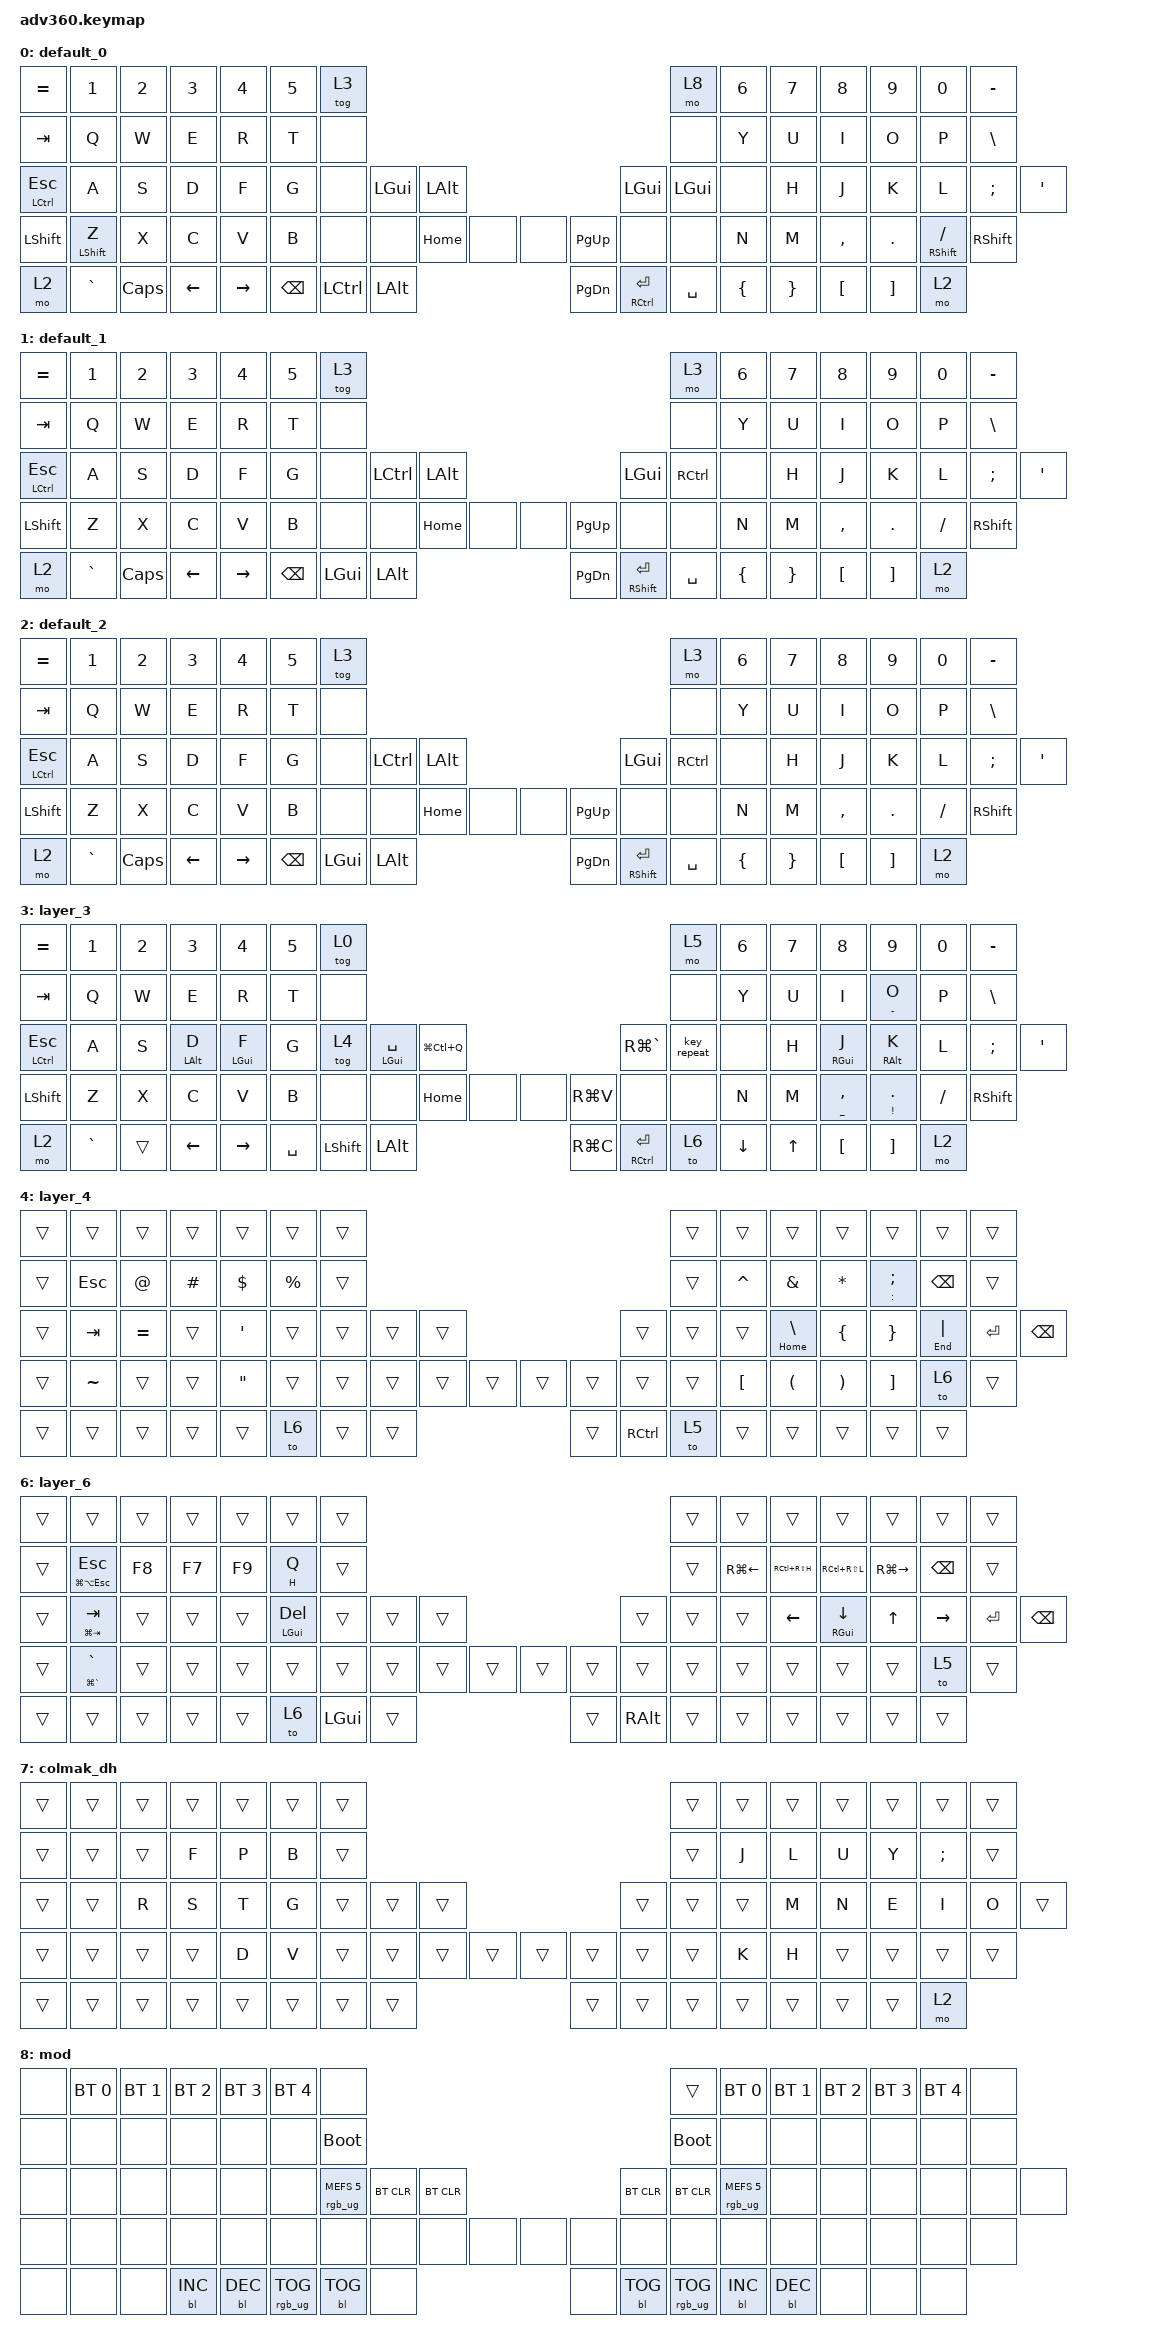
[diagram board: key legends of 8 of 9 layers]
#include <behaviors.dtsi>
#include <dt-bindings/zmk/keys.h>
#include <dt-bindings/zmk/bt.h>
#include <dt-bindings/zmk/rgb.h>
#include <dt-bindings/zmk/backlight.h>

/ {
    behaviors {
        #include "macros.dtsi"

        hm: homerow_mods {
            compatible = "zmk,behavior-hold-tap";
            label = "HOMEROW_MODS";
            #binding-cells = <2>;
            tapping-term-ms = <250>;
            quick_tap_ms = <0>;
            flavor = "tap-preferred";
            bindings =
                <&kp>,
                <&kp>;
        };
        td: tapdance {
            compatible = "zmk,behavior-hold-tap";
            label = "TAPDANCE";
            #binding-cells = <2>;
            tapping-term-ms = <175>;
            quick_tap_ms = <0>;
            flavor = "tap-preferred";
            bindings = <&kp>, <&kp>;
        };
    };

    keymap {
        compatible = "zmk,keymap";

        default_0 {
            bindings = <
            &kp EQUAL     &kp N1    &kp N2    &kp N3     &kp N4  &kp N5    &tog 3                                                                             &mo 8  &kp N6          &kp N7           &kp N8    &kp N9    &kp N0  &kp MINUS
              &kp TAB      &kp Q     &kp W     &kp E      &kp R   &kp T     &none                                                                             &none   &kp Y           &kp U            &kp I     &kp O     &kp P   &kp BSLH
 &hm LEFT_CONTROL ESC      &kp A     &kp S     &kp D      &kp F   &kp G     &none  &kp LGUI  &kp LALT                   &kp LGUI              &kp LGUI      &none   &kp H           &kp J            &kp K     &kp L  &kp SEMI    &kp SQT
            &kp LSHFT      &hm LSHFT Z     &kp X     &kp C      &kp V   &kp B     &none      &none  &kp HOME   &none   &none  &kp PG_UP                  &none      &none   &kp N           &kp M        &kp COMMA   &kp DOT  &hm RSHFT FSLH  &kp RSHFT
                &mo 2  &kp GRAVE  &kp CAPS  &kp LEFT  &kp RIGHT          &kp BSPC   &kp LCTRL  &kp LALT                  &kp PG_DN  &hm RCTRL ENTER  &kp SPACE          &kp LEFT_BRACE  &kp RIGHT_BRACE  &kp LBKT  &kp RBKT      &mo 2
            >;
        };

        default_1 {
            bindings = <
            &kp EQUAL     &kp N1    &kp N2    &kp N3     &kp N4  &kp N5    &tog 3                                                                             &mo 3  &kp N6          &kp N7           &kp N8    &kp N9    &kp N0  &kp MINUS
              &kp TAB      &kp Q     &kp W     &kp E      &kp R   &kp T     &none                                                                             &none   &kp Y           &kp U            &kp I     &kp O     &kp P   &kp BSLH
 &hm LEFT_CONTROL ESC      &kp A     &kp S     &kp D      &kp F   &kp G     &none  &kp LCTRL  &kp LALT                   &kp LGUI              &kp RCTRL      &none   &kp H           &kp J            &kp K     &kp L  &kp SEMI    &kp SQT
            &kp LSHFT      &kp Z     &kp X     &kp C      &kp V   &kp B     &none      &none  &kp HOME   &none   &none  &kp PG_UP                  &none      &none   &kp N           &kp M        &kp COMMA   &kp DOT  &kp FSLH  &kp RSHFT
                &mo 2  &kp GRAVE  &kp CAPS  &kp LEFT  &kp RIGHT          &kp BSPC   &kp LGUI  &kp LALT                  &kp PG_DN  &mt RIGHT_SHIFT ENTER  &kp SPACE          &kp LEFT_BRACE  &kp RIGHT_BRACE  &kp LBKT  &kp RBKT      &mo 2
            >;
        };

        default_2 {
            bindings = <
            &kp EQUAL     &kp N1    &kp N2    &kp N3     &kp N4  &kp N5    &tog 3                                                                             &mo 3  &kp N6          &kp N7           &kp N8    &kp N9    &kp N0  &kp MINUS
              &kp TAB      &kp Q     &kp W     &kp E      &kp R   &kp T     &none                                                                             &none   &kp Y           &kp U            &kp I     &kp O     &kp P   &kp BSLH
 &hm LEFT_CONTROL ESC      &kp A     &kp S     &kp D      &kp F   &kp G     &none  &kp LCTRL  &kp LALT                   &kp LGUI              &kp RCTRL      &none   &kp H           &kp J            &kp K     &kp L  &kp SEMI    &kp SQT
            &kp LSHFT      &kp Z     &kp X     &kp C      &kp V   &kp B     &none      &none  &kp HOME   &none   &none  &kp PG_UP                  &none      &none   &kp N           &kp M        &kp COMMA   &kp DOT  &kp FSLH  &kp RSHFT
                &mo 2  &kp GRAVE  &kp CAPS  &kp LEFT  &kp RIGHT          &kp BSPC   &kp LGUI  &kp LALT                  &kp PG_DN  &mt RIGHT_SHIFT ENTER  &kp SPACE          &kp LEFT_BRACE  &kp RIGHT_BRACE  &kp LBKT  &kp RBKT      &mo 2
            >;
        };

        layer_3 {
            bindings = <
            &kp EQUAL     &kp N1  &kp N2    &kp N3     &kp N4  &kp N5  &tog 0                                                                                        &mo 5  &kp N6    &kp N7     &kp N8    &kp N9    &kp N0  &kp MINUS
              &kp TAB      &kp Q   &kp W     &kp E      &kp R   &kp T   &none                                                                                        &none   &kp Y     &kp U      &kp I     &td MINUS O     &kp P   &kp BSLH
 &mt LCTRL ESC      &kp A   &kp S     &hm LALT D      &hm LGUI F   &kp G  &tog 4    &mt LGUI SPACE  &kp LG(LC(Q))                  &kp RG(GRAVE)            &key_repeat      &none   &kp H     &hm RGUI J      &hm RALT K     &kp L  &kp SEMI    &kp SQT
            &kp LSHFT      &kp Z   &kp X     &kp C      &kp V   &kp B   &none             &none  &kp HOME   &none   &none      &kp RG(V)                  &none      &none   &kp N     &kp M  &td UNDER COMMA   &td EXCL DOT  &kp FSLH  &kp RSHFT
                &mo 2  &kp GRAVE  &trans  &kp LEFT  &kp RIGHT   &kp SPACE  &kp LSHFT   &kp LALT                      &kp RG(C)  &mt RCTRL ENTER  &to 6        &kp DOWN     &kp UP  &kp LBKT  &kp RBKT      &mo 2
            >;
        };

        layer_4 {
            bindings = <
 &trans        &trans        &trans        &trans        &trans        &trans  &trans                                                        &trans        &trans        &trans        &trans        &trans        &trans         &trans
 &trans        &kp ESC       &kp AT        &kp HASH      &kp DLLR      &kp PRCNT &trans                                                        &trans        &kp CARET     &kp AMPS      &kp STAR      &td COLON SEMI     &kp BKSP         &trans
 &trans        &kp TAB       &kp EQUAL     &trans        &kp SQT       &trans      &trans        &trans  &trans                  &trans  &trans  &trans        &td HOME BSLH      &kp LBRC      &kp RBRC      &td END PIPE      &kp ENTER      &kp BKSP
 &trans        &kp TILDE     &trans        &trans        &kp DQT       &trans      &trans        &trans  &trans  &trans  &trans  &trans  &trans  &trans        &kp LBKT      &kp LPAR      &kp RPAR      &kp RBKT      &to 6          &trans
 &trans        &trans        &trans        &trans        &trans        &to 6  &trans &trans                  &trans  &kp RCTL  &to 5                      &trans        &trans        &trans        &trans         &trans
            >;
        };

        layer_5 {
            bindings = <
 &trans        &trans        &trans        &trans        &trans        &trans  &trans                                                        &trans        &trans        &trans        &trans        &trans        &trans         &trans
 &trans  			 &kp ESC  		 &trans 			 &trans  			 &trans  			 &kp UNDER  &trans                                                        &trans        &kp MINUS        &kp N7  &kp N8  &kp N9  &kp BKSP         &trans
 &trans        &kp TAB       &trans        &trans        &trans        &kp PLUS  &trans        &trans  &trans                  &trans  &trans  &trans      	 &kp EQUAL      	 &kp N4  &kp N5  &kp N6  &kp ENTER      &kp BKSP
 &trans        &trans        &trans        &trans        &trans        &kp DOT  &trans        &trans  &trans  &trans  &trans  &trans  &trans  &trans        &kp N0  &kp N1  &kp N2  &kp N3  &to 6   			&trans
 &trans        &trans        &trans        &trans        &trans        &to 6   &kp LGUI       &trans                  &trans  &trans  &to 4                             &trans        &kp N0                   &trans         &trans
            >;
        };

        layer_6 {
            bindings = <
              &trans        &trans        &trans        &trans        &trans        &trans  &trans                                                        &trans        &trans        &trans        &trans        &trans        &trans         &trans
              &trans        &td LG(LA(ESC)) ESC         &kp F8        &kp F7        &kp F9        &td H Q  &trans                                                        &trans        &kp RG(LEFT)        &kp RC(RS(H))        &kp RC(RS(L))         &kp RG(RIGHT)        &kp BKSP         &trans
 &trans        &td LG(TAB) TAB        &trans        &trans        &trans        &td LGUI DELETE    &trans      &trans   &trans     &trans   &trans    &trans    &kp LEFT      &hm RGUI DOWN        &kp UP     &kp RIGHT     &kp ENTER  &kp BKSP
 &trans        &td LG(GRAVE) GRAVE               &trans        &trans        &trans        &trans  &trans        &trans  &trans  &trans  &trans  &trans  &trans  &trans        &trans        &trans        &trans        &trans        &to 5 &trans
 &trans        &trans                 &trans        &trans        &trans        &to 6   &kp LGUI        &trans                  &trans  &kp RALT  &trans                      &trans        &trans        &trans        &trans         &trans
            >;
        };

        colmak_dh {
            bindings = <
 &trans  &trans  &trans  &trans  &trans  &trans  &trans                                                  &trans  &trans  &trans  &trans  &trans    &trans  &trans
 &trans  &trans  &trans   &kp F   &kp P   &kp B  &trans                                                  &trans   &kp J   &kp L   &kp U   &kp Y  &kp SEMI  &trans
 &trans  &trans   &kp R   &kp S   &kp T   &kp G  &trans  &trans  &trans                  &trans  &trans  &trans   &kp M   &kp N   &kp E   &kp I     &kp O  &trans
 &trans  &trans  &trans  &trans   &kp D   &kp V  &trans  &trans  &trans  &trans  &trans  &trans  &trans  &trans   &kp K   &kp H  &trans  &trans    &trans  &trans
 &trans  &trans  &trans  &trans  &trans          &trans  &trans  &trans                  &trans  &trans  &trans          &trans  &trans  &trans    &trans   &mo 2
            >;
        };

        mod {
            bindings = <
  &none  &bt BT_SEL 0  &bt BT_SEL 1  &bt BT_SEL 2  &bt BT_SEL 3  &bt BT_SEL 4                   &none                                                                                  &trans  &bt BT_SEL 0  &bt BT_SEL 1  &bt BT_SEL 2  &bt BT_SEL 3  &bt BT_SEL 4   &none
  &none         &none         &none         &none         &none         &none             &bootloader                                                                             &bootloader         &none         &none         &none         &none         &none   &none
  &none         &none         &none         &none         &none         &none  &rgb_ug RGB_MEFS_CMD 5  &bt BT_CLR  &bt BT_CLR                  &bt BT_CLR  &bt BT_CLR  &rgb_ug RGB_MEFS_CMD 5         &none         &none         &none         &none         &none   &none
  &none         &none         &none         &none         &none         &none                   &none       &none       &none   &none   &none       &none       &none                   &none         &none         &none         &none         &none         &none   &none
  &none         &none         &none    &bl BL_INC    &bl BL_DEC                       &rgb_ug RGB_TOG  &bl BL_TOG       &none                       &none  &bl BL_TOG         &rgb_ug RGB_TOG                  &bl BL_INC    &bl BL_DEC         &none         &none   &none
            >;
        };

    };
};
